# STM32L562 register map
File version: 1.0
CPU: CM33 r0p1, little endian, MPU, FPU, 3 interrupt priority bits
Registers are 32-bit, read-write, reset 0x0 unless marked. A register's access mark holds for its fields unless they carry their own. Offsets are from the block's base; [hi:lo] are bit positions; {n}, {i} and the like mark numbered series; 'fields as' and 'values as' point back to an identical list.

## HASH — Hash processor
Base 0x420C0400
Same registers: SEC_HASH 0x520C0400
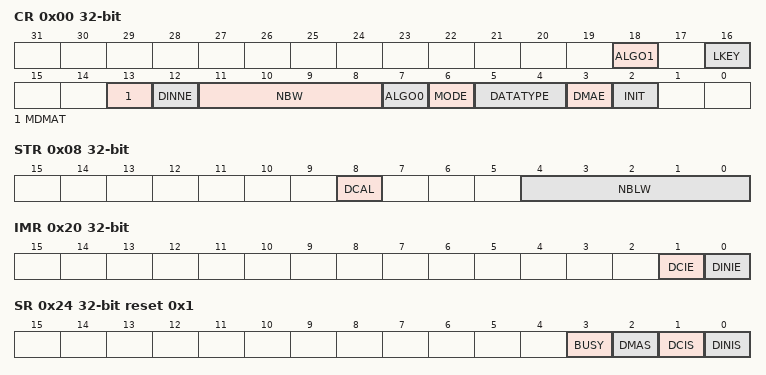
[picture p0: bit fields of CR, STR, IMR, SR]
0x00 CR access per field — control register
  [18] ALGO1 rw — Algorithm selection
  [16] LKEY rw — Long key selection
  [13] MDMAT rw — Multiple DMA Transfers
  [12] DINNE ro — DIN not empty
  [11:8] NBW ro — Number of words already pushed
  [7] ALGO0 rw — Algorithm selection
  [6] MODE rw — Mode selection
  [5:4] DATATYPE rw — Data type selection
  [3] DMAE rw — DMA enable
  [2] INIT wo — Initialize message digest calculation
0x04 DIN — data input register
  [31:0] DATAIN — Data input
0x08 STR — start register
  [8] DCAL — Digest calculation
  [4:0] NBLW — Number of valid bits in the last word of the message
{0xC+4i} HRA{i} ro (i=0..4) — HASH aliased digest register {i}
  [31:0] H{i}
0x20 IMR — interrupt enable register
  [1] DCIE — Digest calculation completion interrupt enable
  [0] DINIE — Data input interrupt enable
0x24 SR access per field reset 0x1 — status register
  [3] BUSY ro — Busy bit
  [2] DMAS ro — DMA Status
  [1] DCIS rw — Digest calculation completion interrupt status
  [0] DINIS rw — Data input interrupt status
0xF8 CSR0 reset 0x2 — context swap registers
{0xF8+4i} CSR{i} (i=1..53) — context swap registers
0x310 HR0 ro — digest register 0
  [31:0] H0
0x314 HR1 ro — digest register 1
  [31:0] H1
0x318 HR2 ro — digest register 4
  [31:0] H2
0x31C HR3 ro — digest register 3
  [31:0] H3
0x320 HR4 ro — digest register 4
  [31:0] H4
{0x310+4i} HR{i} ro (i=5..7) — supplementary digest register {i}
  [31:0] H{i}

## ICACHE
Base 0x40030400
Same registers: SEC_ICache 0x50030400
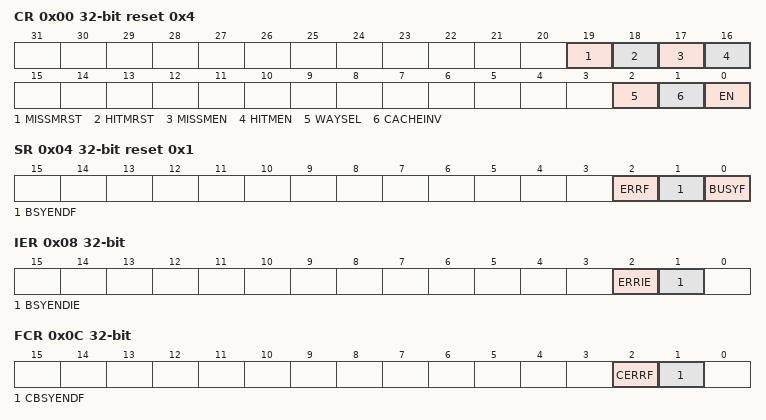
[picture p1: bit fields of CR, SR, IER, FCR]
0x00 CR reset 0x4 — ICACHE control register
  [19] MISSMRST, [18] HITMRST, [17] MISSMEN, [16] HITMEN, [2] WAYSEL, [1] CACHEINV, [0] EN
0x04 SR ro reset 0x1 — ICACHE status register
  [2] ERRF, [1] BSYENDF, [0] BUSYF
0x08 IER — ICACHE interrupt enable register
  [2] ERRIE, [1] BSYENDIE
0x0C FCR wo — ICACHE flag clear register
  [2] CERRF, [1] CBSYENDF
0x10 HMONR ro — ICACHE hit monitor register
  [31:0] HITMON
0x14 MMONR ro — ICACHE miss monitor register
  [15:0] MISSMON
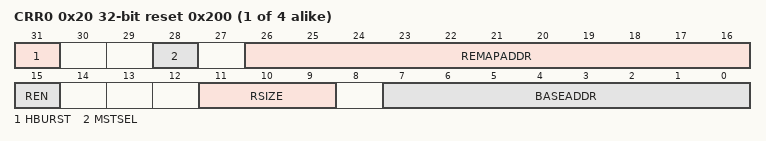
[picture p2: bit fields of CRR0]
{0x20+4i} CRR{i} (i=0..3) reset 0x200 — ICACHE region configuration register
  [31] HBURST, [28] MSTSEL, [26:16] REMAPADDR, [15] REN, [11:9] RSIZE, [7:0] BASEADDR

## IWDG — Independent watchdog
Base 0x40003000
Same registers: SEC_IWDG 0x50003000
0x00 KR 16-bit wo — Key register
  [15:0] KEY — Key value (write only, read 0x0000)
0x04 PR 16-bit — Prescaler register
  [2:0] PR — Prescaler divider
0x08 RLR 16-bit reset 0xFFF — Reload register
  [11:0] RL — Watchdog counter reload value
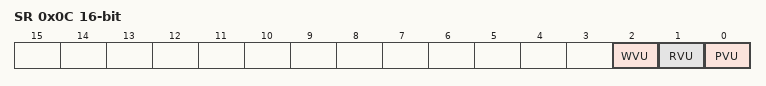
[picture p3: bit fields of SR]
0x0C SR 16-bit ro — Status register
  [2] WVU — Watchdog counter window value update
  [1] RVU — Watchdog counter reload value update
  [0] PVU — Watchdog prescaler value update
0x10 WINR 16-bit reset 0xFFF — Window register
  [11:0] WIN — Watchdog counter window value

## OPAMP — Operational amplifiers
Base 0x40007800
Same registers: SEC_OPAMP 0x50007800
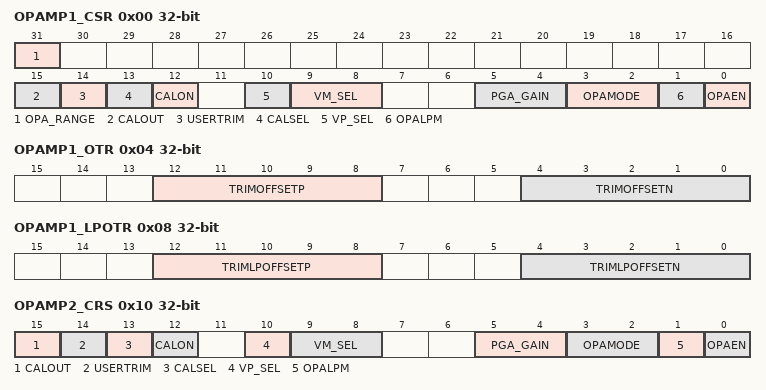
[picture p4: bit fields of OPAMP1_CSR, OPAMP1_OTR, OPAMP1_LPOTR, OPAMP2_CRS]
0x00 OPAMP1_CSR — OPAMP1 control/status register
  [31] OPA_RANGE — Operational amplifier power supply range for stability
  [15] CALOUT — Operational amplifier calibration output
  [14] USERTRIM — User trimming enable
  [13] CALSEL — calibration selection
  [12] CALON — calibration mode enable
  [10] VP_SEL — non inverted input selection
  [9:8] VM_SEL — inverting input selection
  [5:4] PGA_GAIN — Operational amplifier Programmable amplifier gain value
  [3:2] OPAMODE — Operational amplifier PGA mode
  [1] OPALPM — Operational amplifier Low Power Mode
  [0] OPAEN — Operational amplifier Enable
0x04 OPAMP1_OTR — OPAMP1 offset trimming register in normal mode
  [12:8] TRIMOFFSETP — Trim for PMOS differential pairs
  [4:0] TRIMOFFSETN — Trim for NMOS differential pairs
0x08 OPAMP1_LPOTR — OPAMP1 offset trimming register in low-powe mode
  [12:8] TRIMLPOFFSETP — Trim for PMOS differential pairs
  [4:0] TRIMLPOFFSETN — Trim for NMOS differential pairs
0x10 OPAMP2_CRS — OPAMP2 control/status register
  [15] CALOUT — Operational amplifier calibration output
  [14] USERTRIM — User trimming enable
  [13] CALSEL — calibration selection
  [12] CALON — calibration mode enable
  [10] VP_SEL — non inverted input selection
  [9:8] VM_SEL — inverting input selection
  [5:4] PGA_GAIN — Operational amplifier Programmable amplifier gain value
  [3:2] OPAMODE — Operational amplifier PGA mode
  [1] OPALPM — Operational amplifier Low Power Mode
  [0] OPAEN — Operational amplifier Enable
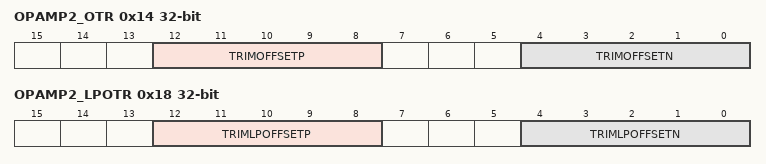
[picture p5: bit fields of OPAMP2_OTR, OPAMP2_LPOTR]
0x14 OPAMP2_OTR — OPAMP2 offset trimming register in normal mode
  fields as OPAMP1_OTR
0x18 OPAMP2_LPOTR — OPAMP2 offset trimming register in low-power mode
  fields as OPAMP1_LPOTR
